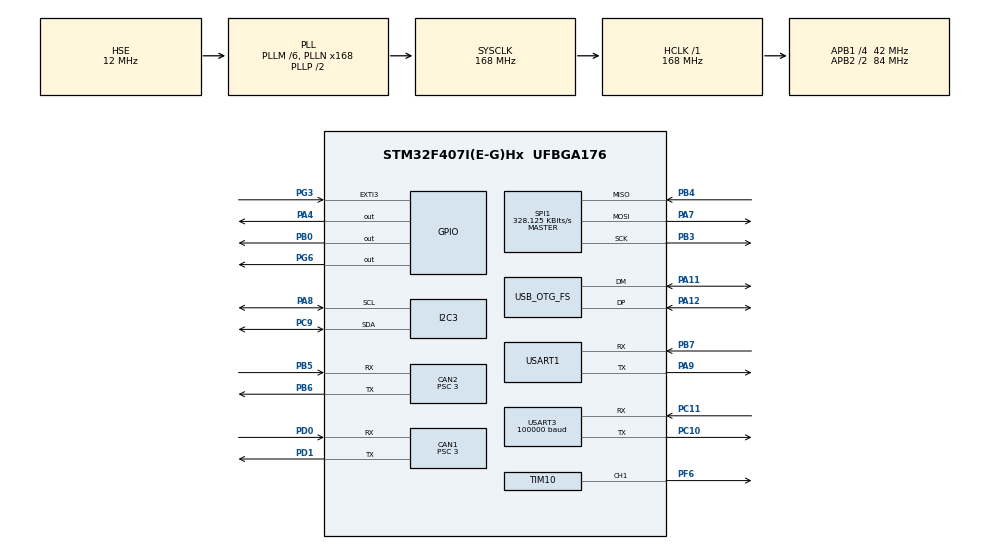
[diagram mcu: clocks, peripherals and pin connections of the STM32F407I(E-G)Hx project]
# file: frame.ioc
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CAN1.AWUM=ENABLE
CAN1.BS1=CAN_BS1_10TQ
CAN1.BS2=CAN_BS2_3TQ
CAN1.CalculateBaudRate=1000000
CAN1.CalculateTimeBit=1000
CAN1.CalculateTimeQuantum=71.42857142857143
CAN1.NART=ENABLE
CAN1.Prescaler=3
CAN1.TXFP=ENABLE
CAN2.BS1=CAN_BS1_10TQ
CAN2.BS2=CAN_BS2_3TQ
CAN2.CalculateBaudRate=1000000
CAN2.CalculateTimeBit=1000
CAN2.CalculateTimeQuantum=71.42857142857143
CAN2.Prescaler=3
Dma.Request0=USART1_TX
Dma.Request1=USART3_RX
Dma.USART1_TX.0.Direction=DMA_MEMORY_TO_PERIPH
Dma.USART1_TX.0.FIFOMode=DMA_FIFOMODE_DISABLE
Dma.USART1_TX.0.Instance=DMA2_Stream7
Dma.USART1_TX.0.MemDataAlignment=DMA_MDATAALIGN_BYTE
Dma.USART1_TX.0.MemInc=DMA_MINC_ENABLE
Dma.USART1_TX.0.Mode=DMA_NORMAL
Dma.USART1_TX.0.PeriphDataAlignment=DMA_PDATAALIGN_BYTE
Dma.USART1_TX.0.PeriphInc=DMA_PINC_DISABLE
Dma.USART1_TX.0.Priority=DMA_PRIORITY_LOW
Dma.USART3_RX.1.Direction=DMA_PERIPH_TO_MEMORY
Dma.USART3_RX.1.FIFOMode=DMA_FIFOMODE_DISABLE
Dma.USART3_RX.1.Instance=DMA1_Stream1
Dma.USART3_RX.1.MemDataAlignment=DMA_MDATAALIGN_BYTE
Dma.USART3_RX.1.MemInc=DMA_MINC_ENABLE
Dma.USART3_RX.1.Mode=DMA_CIRCULAR
Dma.USART3_RX.1.PeriphDataAlignment=DMA_PDATAALIGN_BYTE
Dma.USART3_RX.1.PeriphInc=DMA_PINC_DISABLE
Dma.USART3_RX.1.Priority=DMA_PRIORITY_VERY_HIGH
FREERTOS.INCLUDE_uxTaskGetStackHighWaterMark=1
FREERTOS.Tasks01=defaultTask,0,128,StartDefaultTask,Default,NULL,Dynamic,NULL,NULL;Isttask,2,512,isttask,As weak,NULL,Dynamic,NULL,NULL;Chassis_task,-3,512,StartChassisTask,As weak,NULL,Dynamic,NULL,NULL;CommandTask,2,512,StartCommandTask,As weak,NULL,Dynamic,NULL,NULL
FREERTOS.configENABLE_FPU=1
FREERTOS.configGENERATE_RUN_TIME_STATS=1
FREERTOS.configUSE_STATS_FORMATTING_FUNCTIONS=1
FREERTOS.configUSE_TIMERS=1
FREERTOS.configUSE_TRACE_FACILITY=1
I2C3.I2C_Mode=I2C_Fast
Mcu.Family=STM32F4
Mcu.Name=STM32F407I(E-G)Hx
Mcu.Package=UFBGA176
NVIC.CAN1_RX0_IRQn=true\:5\:0\:false\:false\:true\:true\:true\:true\:true
NVIC.CAN2_RX1_IRQn=true\:5\:0\:false\:false\:true\:true\:true\:true\:true
NVIC.DMA1_Stream1_IRQn=true\:5\:0\:false\:false\:true\:true\:false\:true\:true
NVIC.DMA2_Stream7_IRQn=true\:5\:0\:false\:false\:true\:true\:false\:true\:true
NVIC.EXTI3_IRQn=true\:5\:0\:false\:false\:true\:true\:true\:true\:true
NVIC.OTG_FS_IRQn=true\:5\:0\:false\:false\:true\:true\:false\:true\:true
NVIC.PriorityGroup=NVIC_PRIORITYGROUP_4
NVIC.TIM1_UP_TIM10_IRQn=true\:5\:0\:false\:false\:true\:true\:true\:true\:true
NVIC.TIM4_IRQn=true\:5\:0\:false\:false\:true\:true\:true\:true\:true
NVIC.TIM8_TRG_COM_TIM14_IRQn=true\:15\:0\:false\:false\:true\:false\:false\:true\:true
NVIC.TimeBase=TIM8_TRG_COM_TIM14_IRQn
NVIC.TimeBaseIP=TIM14
NVIC.USART3_IRQn=true\:5\:0\:false\:false\:true\:true\:true\:true\:true
PA11.Mode=Device_Only
PA11.Signal=USB_OTG_FS_DM
PA12.Mode=Device_Only
PA12.Signal=USB_OTG_FS_DP
PA13.Mode=Serial_Wire
PA13.Signal=SYS_JTMS-SWDIO
PA14.Mode=Serial_Wire
PA14.Signal=SYS_JTCK-SWCLK
PA4.PinState=GPIO_PIN_SET
PA4.Signal=GPIO_Output
PA7.Mode=Full_Duplex_Master
PA7.Signal=SPI1_MOSI
PA8.Mode=I2C
PA8.Signal=I2C3_SCL
PA9.Mode=Asynchronous
PA9.Signal=USART1_TX
PB0.PinState=GPIO_PIN_SET
PB0.Signal=GPIO_Output
PB3.Mode=Full_Duplex_Master
PB3.Signal=SPI1_SCK
PB4.Mode=Full_Duplex_Master
PB4.Signal=SPI1_MISO
PB5.Mode=CAN_Activate
PB5.Signal=CAN2_RX
PB6.Mode=CAN_Activate
PB6.Signal=CAN2_TX
PB7.Mode=Asynchronous
PB7.Signal=USART1_RX
PC10.Mode=Asynchronous
PC10.Signal=USART3_TX
PC11.Mode=Asynchronous
PC11.Signal=USART3_RX
PC14-OSC32_IN.Mode=LSE-External-Oscillator
PC14-OSC32_IN.Signal=RCC_OSC32_IN
PC15-OSC32_OUT.Mode=LSE-External-Oscillator
PC15-OSC32_OUT.Signal=RCC_OSC32_OUT
PC9.Mode=I2C
PC9.Signal=I2C3_SDA
PD0.Mode=CAN_Activate
PD0.Signal=CAN1_RX
PD1.Mode=CAN_Activate
PD1.Signal=CAN1_TX
PF6.Signal=S_TIM10_CH1
PG3.GPIO_ModeDefaultEXTI=GPIO_MODE_IT_FALLING
PG3.Signal=GPXTI3
PG6.GPIO_PuPd=GPIO_PULLUP
PG6.PinState=GPIO_PIN_SET
PG6.Signal=GPIO_Output
PH0-OSC_IN.Mode=HSE-External-Oscillator
PH0-OSC_IN.Signal=RCC_OSC_IN
PH1-OSC_OUT.Mode=HSE-External-Oscillator
PH1-OSC_OUT.Signal=RCC_OSC_OUT
ProjectManager.HeapSize=0x400
ProjectManager.StackSize=0x400
ProjectManager.TargetToolchain=MDK-ARM V5.32
RCC.48MHZClocksFreq_Value=48000000
RCC.AHBFreq_Value=168000000
RCC.APB1CLKDivider=RCC_HCLK_DIV4
RCC.APB1Freq_Value=42000000
RCC.APB1TimFreq_Value=84000000
RCC.APB2CLKDivider=RCC_HCLK_DIV2
RCC.APB2Freq_Value=84000000
RCC.APB2TimFreq_Value=168000000
RCC.CortexFreq_Value=168000000
RCC.HCLKFreq_Value=168000000
RCC.HSE_VALUE=12000000
RCC.HSI_VALUE=16000000
RCC.PLLM=6
RCC.PLLN=168
RCC.PLLQ=7
RCC.SYSCLKFreq_VALUE=168000000
RCC.SYSCLKSource=RCC_SYSCLKSOURCE_PLLCLK
RCC.VCOOutputFreq_Value=336000000
SH.S_TIM10_CH1.0=TIM10_CH1,PWM Generation1 CH1
SPI1.BaudRatePrescaler=SPI_BAUDRATEPRESCALER_256
SPI1.CLKPhase=SPI_PHASE_2EDGE
SPI1.CLKPolarity=SPI_POLARITY_HIGH
SPI1.CalculateBaudRate=328.125 KBits/s
SPI1.Direction=SPI_DIRECTION_2LINES
SPI1.Mode=SPI_MODE_MASTER
SPI1.VirtualType=VM_MASTER
STMicroelectronics.X-CUBE-ALGOBUILD.1.4.0.LibraryCcDSPOoLibraryJjDSPOoLibrary=true
TIM10.Channel=TIM_CHANNEL_1
TIM2.ClockDivision=TIM_CLOCKDIVISION_DIV2
TIM2.Prescaler=8399
TIM4.AutoReloadPreload=TIM_AUTORELOAD_PRELOAD_ENABLE
TIM4.Period=9999
TIM4.Prescaler=8399
USART1.VirtualMode=VM_ASYNC
USART3.BaudRate=100000
USART3.Parity=PARITY_EVEN
USART3.VirtualMode=VM_ASYNC
USART3.WordLength=WORDLENGTH_9B
USB_DEVICE.CLASS_NAME_FS=CDC
USB_DEVICE.VirtualMode-CDC_FS=Cdc
USB_DEVICE.VirtualModeFS=Cdc_FS
USB_OTG_FS.VirtualMode=Device_Only
VP_FREERTOS_VS_CMSIS_V1.Mode=CMSIS_V1
VP_STMicroelectronics.X-CUBE-ALGOBUILD_VS_DSPOoLibraryJjLibrary_1.4.0_1.4.0.Mode=DSPOoLibraryJjLibrary
VP_SYS_VS_tim14.Mode=TIM14
VP_TIM10_VS_ClockSourceINT.Mode=Enable_Timer
VP_TIM2_VS_ClockSourceINT.Mode=Internal
VP_TIM4_VS_ClockSourceINT.Mode=Internal
VP_USB_DEVICE_VS_USB_DEVICE_CDC_FS.Mode=CDC_FS
board=custom

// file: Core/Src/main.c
/* USER CODE BEGIN Header */
/**
  ******************************************************************************
  * @file           : main.c
  * @brief          : Main program body
  ******************************************************************************
  * @attention
  *
  * Copyright (c) 2025 STMicroelectronics.
  * All rights reserved.
  *
  * This software is licensed under terms that can be found in the LICENSE file
  * in the root directory of this software component.
  * If no LICENSE file comes with this software, it is provided AS-IS.
  *
  ******************************************************************************
  */
/* USER CODE END Header */
#include "main.h"
#include "cmsis_os.h"
#include "can.h"
#include "dma.h"
#include "i2c.h"
#include "spi.h"
#include "tim.h"
#include "usart.h"
#include "usb_device.h"
#include "gpio.h"

/* USER CODE BEGIN Includes */
#include "app_gimbal_task.h"
#include "bsp_log.h"
#include "bsp_can.h"
#include "bsp_dwt.h"
/* USER CODE END Includes */

void SystemClock_Config(void);
void MX_FREERTOS_Init(void);

int main(void)

{

  /* MCU Configuration--------------------------------------------------------*/

  /* Reset of all peripherals, Initializes the Flash interface and the Systick. */
  HAL_Init();

  /* Configure the system clock */
  SystemClock_Config();

  /* Initialize all configured peripherals */
  MX_GPIO_Init();
  MX_DMA_Init();
  MX_CAN1_Init();
  MX_CAN2_Init();
  MX_I2C3_Init();
  MX_USART1_UART_Init();
  MX_USART3_UART_Init();
  MX_SPI1_Init();
  MX_TIM10_Init();
  MX_TIM2_Init();
  MX_TIM4_Init();
  /* USER CODE BEGIN 2 */
	DWT_Init(168);
  Log_Init();
//  Can_Init();
  /* USER CODE END 2 */

  /* Call init function for freertos objects (in cmsis_os2.c) */
  MX_FREERTOS_Init();

  /* Start scheduler */
  osKernelStart();

  /* We should never get here as control is now taken by the scheduler */

  /* Infinite loop */
  while (1)
  {

  }
}

void SystemClock_Config(void)
{
  RCC_OscInitTypeDef RCC_OscInitStruct = {0};
  RCC_ClkInitTypeDef RCC_ClkInitStruct = {0};

  /** Configure the main internal regulator output voltage
  */
  __HAL_RCC_PWR_CLK_ENABLE();
  __HAL_PWR_VOLTAGESCALING_CONFIG(PWR_REGULATOR_VOLTAGE_SCALE1);

  /** Initializes the RCC Oscillators according to the specified parameters
  * in the RCC_OscInitTypeDef structure.
  */
  RCC_OscInitStruct.OscillatorType = RCC_OSCILLATORTYPE_HSE;
  RCC_OscInitStruct.HSEState = RCC_HSE_ON;
  RCC_OscInitStruct.PLL.PLLState = RCC_PLL_ON;
  RCC_OscInitStruct.PLL.PLLSource = RCC_PLLSOURCE_HSE;
  RCC_OscInitStruct.PLL.PLLM = 6;
  RCC_OscInitStruct.PLL.PLLN = 168;
  RCC_OscInitStruct.PLL.PLLP = RCC_PLLP_DIV2;
  RCC_OscInitStruct.PLL.PLLQ = 7;
  if (HAL_RCC_OscConfig(&RCC_OscInitStruct) != HAL_OK)
  {
    Error_Handler();
  }

  /** Initializes the CPU, AHB and APB buses clocks
  */
  RCC_ClkInitStruct.ClockType = RCC_CLOCKTYPE_HCLK|RCC_CLOCKTYPE_SYSCLK
                              |RCC_CLOCKTYPE_PCLK1|RCC_CLOCKTYPE_PCLK2;
  RCC_ClkInitStruct.SYSCLKSource = RCC_SYSCLKSOURCE_PLLCLK;
  RCC_ClkInitStruct.AHBCLKDivider = RCC_SYSCLK_DIV1;
  RCC_ClkInitStruct.APB1CLKDivider = RCC_HCLK_DIV4;
  RCC_ClkInitStruct.APB2CLKDivider = RCC_HCLK_DIV2;

  if (HAL_RCC_ClockConfig(&RCC_ClkInitStruct, FLASH_LATENCY_5) != HAL_OK)
  {
    Error_Handler();
  }
}

void HAL_TIM_PeriodElapsedCallback(TIM_HandleTypeDef *htim)
{
  if (htim->Instance == TIM14)
  {
    HAL_IncTick();
  }
}

void Error_Handler(void)
{
  __disable_irq();
  while (1)
  {
  }
}

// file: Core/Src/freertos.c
/* USER CODE BEGIN Header */
/**
  ******************************************************************************
  * File Name          : freertos.c
  * Description        : Code for freertos applications
  ******************************************************************************
  * @attention
  *
  * Copyright (c) 2025 STMicroelectronics.
  * All rights reserved.
  *
  * This software is licensed under terms that can be found in the LICENSE file
  * in the root directory of this software component.
  * If no LICENSE file comes with this software, it is provided AS-IS.
  *
  ******************************************************************************
  */
/* USER CODE END Header */

#include "FreeRTOS.h"
#include "task.h"
#include "main.h"
#include "cmsis_os.h"

osThreadId defaultTaskHandle;
osThreadId IsttaskHandle;
osThreadId Gimbal_TaskHandle;
osThreadId ShooterTaskHandle;
osThreadId CommandTaskHandle;

void StartDefaultTask(void const * argument);
void isttask(void const * argument);
void StartGimbalTask(void const * argument);
void StartShooterTask(void const * argument);
void StartCommandTask(void const * argument);

extern void MX_USB_DEVICE_Init(void);
void MX_FREERTOS_Init(void); /* (MISRA C 2004 rule 8.1) */

/* GetIdleTaskMemory prototype (linked to static allocation support) */
void vApplicationGetIdleTaskMemory( StaticTask_t **ppxIdleTaskTCBBuffer, StackType_t **ppxIdleTaskStackBuffer, uint32_t *pulIdleTaskStackSize );

/* GetTimerTaskMemory prototype (linked to static allocation support) */
void vApplicationGetTimerTaskMemory( StaticTask_t **ppxTimerTaskTCBBuffer, StackType_t **ppxTimerTaskStackBuffer, uint32_t *pulTimerTaskStackSize );

/* Hook prototypes */
void configureTimerForRunTimeStats(void);
unsigned long getRunTimeCounterValue(void);

/* USER CODE BEGIN 1 */
/* Functions needed when configGENERATE_RUN_TIME_STATS is on */
__weak void configureTimerForRunTimeStats(void)
{

}

__weak unsigned long getRunTimeCounterValue(void)
{
return 0;
}
/* USER CODE END 1 */

/* USER CODE BEGIN GET_IDLE_TASK_MEMORY */
static StaticTask_t xIdleTaskTCBBuffer;
static StackType_t xIdleStack[configMINIMAL_STACK_SIZE];

void vApplicationGetIdleTaskMemory( StaticTask_t **ppxIdleTaskTCBBuffer, StackType_t **ppxIdleTaskStackBuffer, uint32_t *pulIdleTaskStackSize )
{
  *ppxIdleTaskTCBBuffer = &xIdleTaskTCBBuffer;
  *ppxIdleTaskStackBuffer = &xIdleStack[0];
  *pulIdleTaskStackSize = configMINIMAL_STACK_SIZE;
  /* place for user code */
}
/* USER CODE END GET_IDLE_TASK_MEMORY */

/* USER CODE BEGIN GET_TIMER_TASK_MEMORY */
static StaticTask_t xTimerTaskTCBBuffer;
static StackType_t xTimerStack[configTIMER_TASK_STACK_DEPTH];

void vApplicationGetTimerTaskMemory( StaticTask_t **ppxTimerTaskTCBBuffer, StackType_t **ppxTimerTaskStackBuffer, uint32_t *pulTimerTaskStackSize )
{
  *ppxTimerTaskTCBBuffer = &xTimerTaskTCBBuffer;
  *ppxTimerTaskStackBuffer = &xTimerStack[0];
  *pulTimerTaskStackSize = configTIMER_TASK_STACK_DEPTH;
  /* place for user code */
}
/* USER CODE END GET_TIMER_TASK_MEMORY */

void MX_FREERTOS_Init(void) {

  /* Create the thread(s) */
  /* definition and creation of defaultTask */
  osThreadDef(defaultTask, StartDefaultTask, osPriorityNormal, 0, 128);
  defaultTaskHandle = osThreadCreate(osThread(defaultTask), NULL);

  /* definition and creation of Isttask */
  osThreadDef(Isttask, isttask, osPriorityHigh, 0, 512);
  IsttaskHandle = osThreadCreate(osThread(Isttask), NULL);

  /* definition and creation of Gimbal_Task */
  osThreadDef(Gimbal_Task, StartGimbalTask, osPriorityNormal, 0, 512);
  Gimbal_TaskHandle = osThreadCreate(osThread(Gimbal_Task), NULL);

  /* definition and creation of ShooterTask */
  osThreadDef(ShooterTask, StartShooterTask, osPriorityNormal, 0, 512);
  ShooterTaskHandle = osThreadCreate(osThread(ShooterTask), NULL);

  /* definition and creation of CommandTask */
  osThreadDef(CommandTask, StartCommandTask, osPriorityHigh, 0, 128);
  CommandTaskHandle = osThreadCreate(osThread(CommandTask), NULL);

}

void StartDefaultTask(void const * argument)
{
  /* init code for USB_DEVICE */
  MX_USB_DEVICE_Init();
  for(;;)
  {
    osDelay(1);
  }
}

__weak void isttask(void const * argument)
{
  for(;;)
  {
    osDelay(1);
  }
}

__weak void StartGimbalTask(void const * argument)
{
  for(;;)
  {
    osDelay(1);
  }
}

__weak void StartShooterTask(void const * argument)
{
  for(;;)
  {
    osDelay(1);
  }
}

__weak void StartCommandTask(void const * argument)
{
  for(;;)
  {
    osDelay(1);
  }
}
